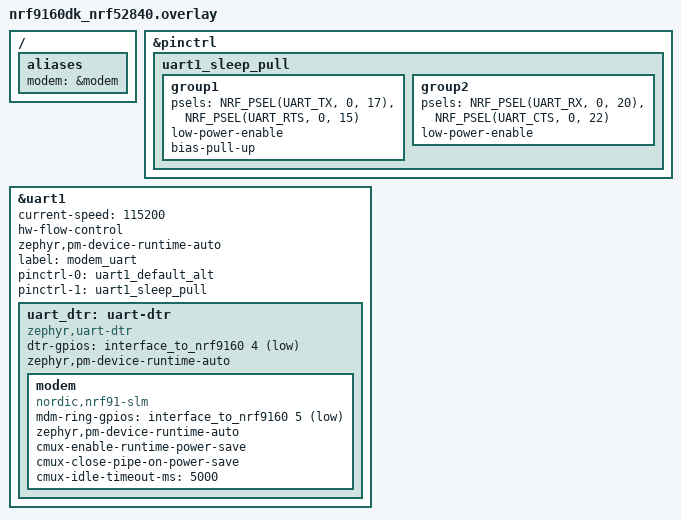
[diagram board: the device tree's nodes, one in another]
#include <nrf52840/nrf9160dk_uart1_on_if0_3.dtsi>

/ {
	aliases {
		modem = &modem;
	};
};

&pinctrl {
	uart1_sleep_pull: uart1_sleep_pull {
		group1 {
			psels = <NRF_PSEL(UART_TX, 0, 17)>,
				<NRF_PSEL(UART_RTS, 0, 15)>;
			low-power-enable;
			bias-pull-up;
		};
		group2 {
			psels = <NRF_PSEL(UART_RX, 0, 20)>,
				<NRF_PSEL(UART_CTS, 0, 22)>;
			low-power-enable;
		};
	};

};

&uart1 {
	current-speed = <115200>;
	hw-flow-control;
	zephyr,pm-device-runtime-auto;
	label = "modem_uart";
	status = "okay";
	pinctrl-0 = <&uart1_default_alt>;
	pinctrl-1 = <&uart1_sleep_pull>;
	pinctrl-names = "default", "sleep";

	uart_dtr: uart-dtr {
		compatible = "zephyr,uart-dtr";
		dtr-gpios = <&interface_to_nrf9160 4 GPIO_ACTIVE_LOW>;
		status = "okay";
		zephyr,pm-device-runtime-auto;

		modem: modem {
			compatible = "nordic,nrf91-slm";
			status = "okay";
			mdm-ring-gpios = <&interface_to_nrf9160 5 (GPIO_PULL_UP | GPIO_ACTIVE_LOW)>;
			zephyr,pm-device-runtime-auto;
			cmux-enable-runtime-power-save;
			cmux-close-pipe-on-power-save;
			cmux-idle-timeout-ms = <5000>;
		};
	};
};
